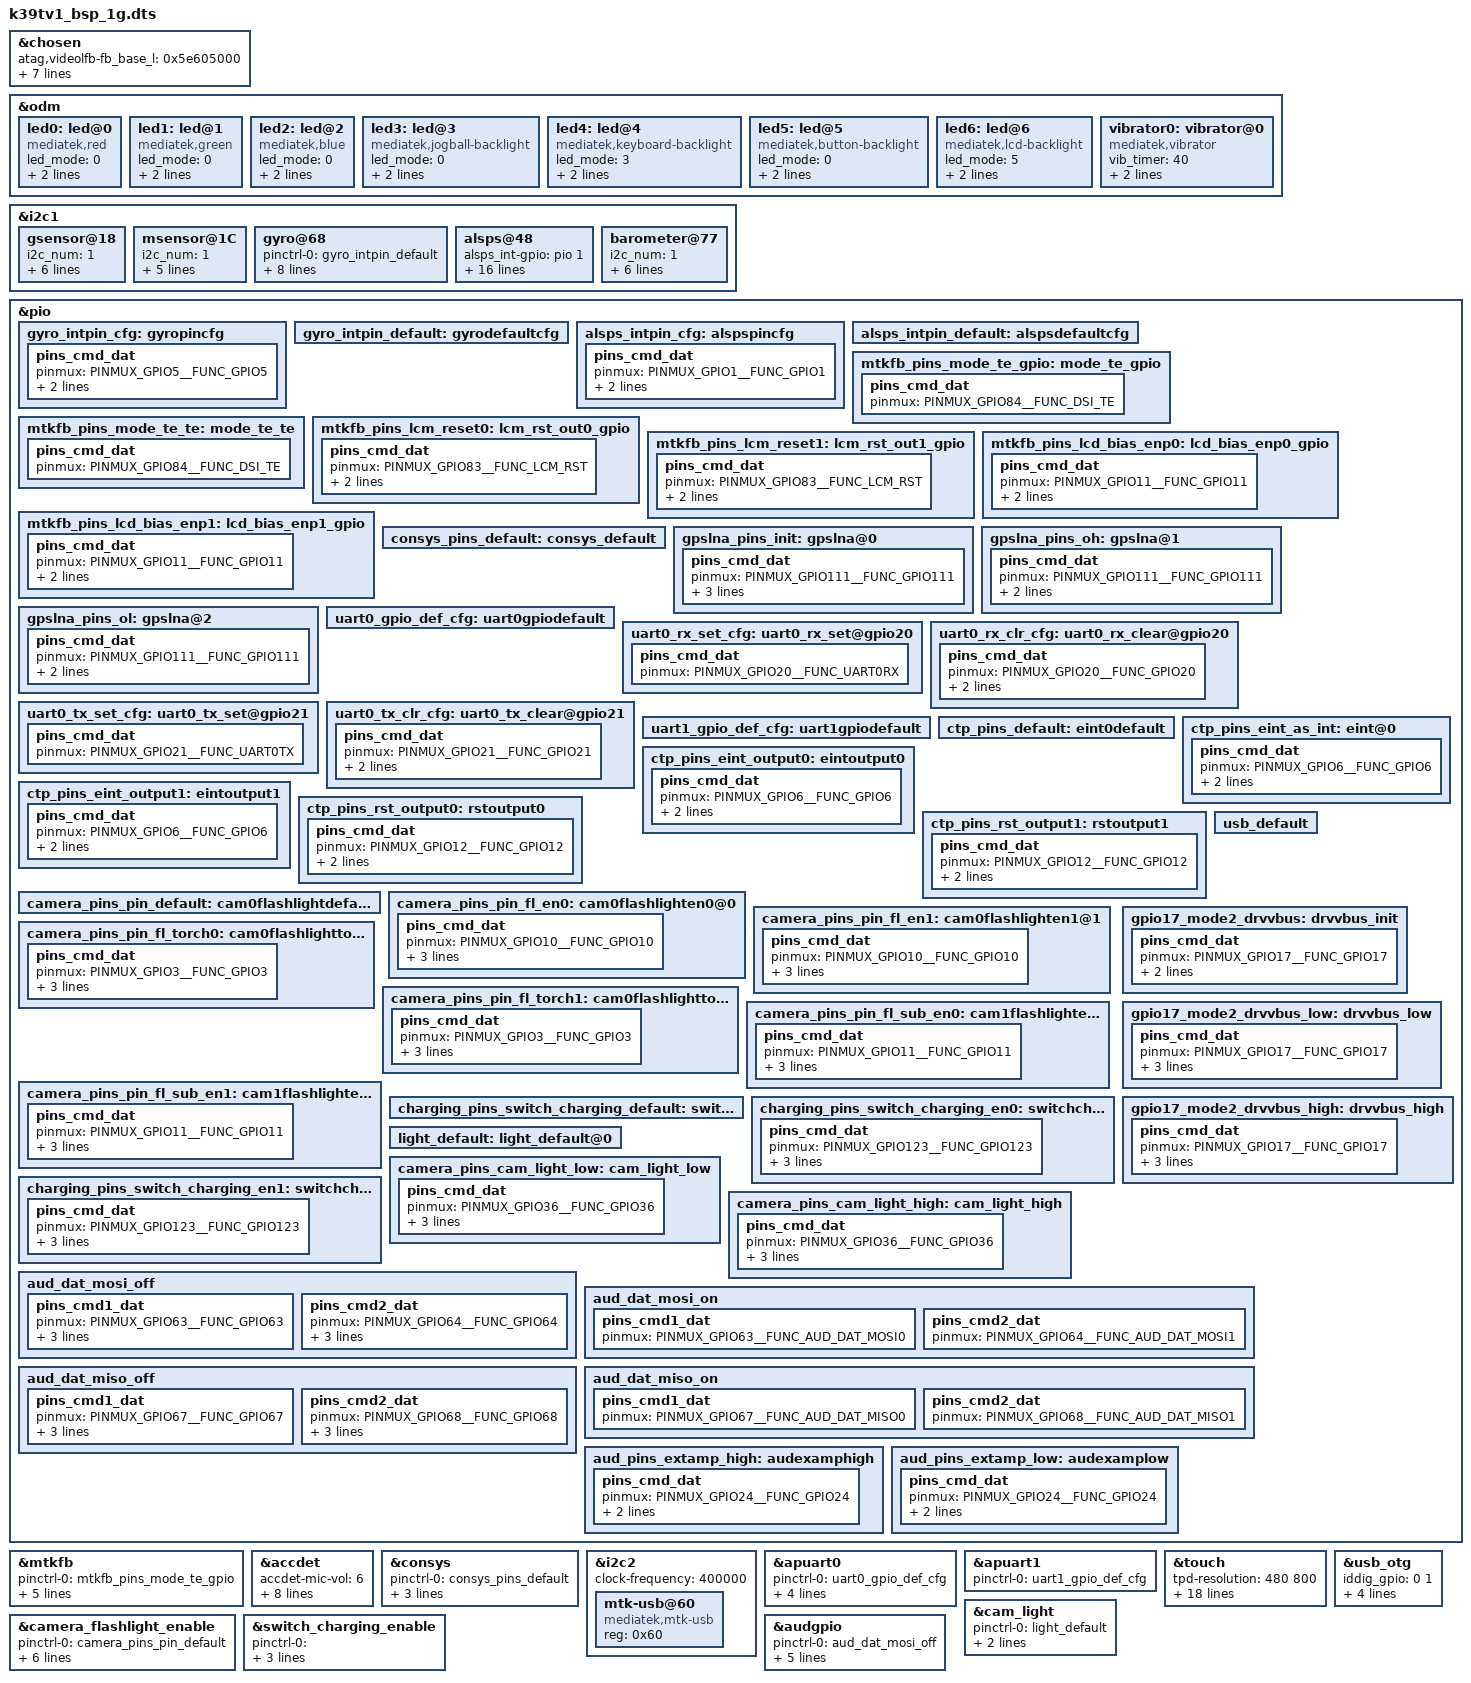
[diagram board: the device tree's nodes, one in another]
/*
 * Mediatek's MT6739 SoC device tree source
 *
 * Copyright (C) 2016 MediaTek Inc.
 *
 * This program is free software; you can redistribute it and/or modify
 * it under the terms of the GNU General Public License version 2 as
 * published by the Free Software Foundation.
 *
 * This program is distributed in the hope that it will be useful,
 * but WITHOUT ANY WARRANTY; without even the implied warranty of
 * MERCHANTABILITY or FITNESS FOR A PARTICULAR PURPOSE.
 * See http://www.gnu.org/licenses/gpl-2.0.html for more details.
 */
#include <generated/autoconf.h>
/dts-v1/;

/plugin/;
#include <dt-bindings/clock/mt6739-clk.h>
#include <dt-bindings/interrupt-controller/arm-gic.h>
#include <dt-bindings/interrupt-controller/irq.h>
#include <dt-bindings/mmc/mt6739-msdc.h>
#include <dt-bindings/pinctrl/mt6739-pinfunc.h>

/* chosen */
&chosen {
	/* fpga may has no lk, we need to specify display info here */
	/* fb buffer is reserved using this dts by memory node above */

	atag,videolfb-fb_base_l = <0x5e605000>;
	atag,videolfb-fb_base_h = <0>;
	atag,videolfb-islcmfound = <1>;
	atag,videolfb-islcm_inited = <0>;
	atag,videolfb-fps= <6000>;
	atag,videolfb-vramSize= <0x017bb000>;
	atag,videolfb-lcmname= "nt35521_hd_dsi_vdo_truly_nt50358_drv";
};

&odm {
	led0:led@0 {
		compatible = "mediatek,red";
		led_mode = <0>;
		data = <1>;
		pwm_config = <0 0 0 0 0>;
	};
	led1:led@1 {
		compatible = "mediatek,green";
		led_mode = <0>;
		data = <1>;
		pwm_config = <0 0 0 0 0>;
	};
	led2:led@2 {
		compatible = "mediatek,blue";
		led_mode = <0>;
		data = <1>;
		pwm_config = <0 0 0 0 0>;
	};
	led3:led@3 {
		compatible = "mediatek,jogball-backlight";
		led_mode = <0>;
		data = <1>;
		pwm_config = <0 0 0 0 0>;
	};
	led4:led@4 {
		compatible = "mediatek,keyboard-backlight";
		led_mode = <3>;
		data = <2>;
		pwm_config = <0 0 0 0 0>;
	};
	led5:led@5 {
		compatible = "mediatek,button-backlight";
		led_mode = <0>;
		data = <1>;
		pwm_config = <0 0 0 0 0>;
	};
	led6:led@6 {
		compatible = "mediatek,lcd-backlight";
		led_mode = <5>;
		data = <1>;
		pwm_config = <0 2 0 0 0>;
	};
	vibrator0:vibrator@0 {
		compatible = "mediatek,vibrator";
		vib_timer = <40>;
		vib_limit = <9>;
		vib_vol= <11>;
	};
};

&i2c1 {
/*  start sensor */
	 gsensor@18 {
		i2c_num = <1>;
		i2c_addr = <0x18 0 0 0>;
		direction = <6>;
		power_id = <0xffff>;
		power_vol = <0>;
		firlen = <1>;
		is_batch_supported = <0>;
	};

	msensor@1C {
		i2c_num = <1>; 
		i2c_addr = <0x1C 0 0 0>;
		direction = <6>;
		power_id = <0xffff>;
		power_vol = <0>;
		is_batch_supported = <0>;
	};

	gyro@68 {
		pinctrl-names = "pin_default", "pin_cfg";
		pinctrl-0 = <&gyro_intpin_default>;
		pinctrl-1 = <&gyro_intpin_cfg>;
		i2c_num = <1>;
		i2c_addr = <0x68 0 0 0>;
		direction = <5>;
		power_id = <0xffff>;
		power_vol = <0>;
		firlen = <0>;
		is_batch_supported = <0>;
	};

	alsps@48{
		alsps_int-gpio = <&pio 1 0>;		
		pinctrl-names = "pin_default", "pin_cfg";
		pinctrl-0 = <&alsps_intpin_default>;
		pinctrl-1 = <&alsps_intpin_cfg>;
		status = "okay";
		/* customization */
		i2c_num = <1>;
		i2c_addr = <0x48 0 0 0>;
		polling_mode_ps = <0>;
		polling_mode_als = <1>;
		power_id = <0xffff>;
		power_vol = <0>;
		als_level = <5 9 36 59 82 132 205 273 500 845 1136 1545 2364 4655 6982>;
		als_value = <10 10 80 85 90 145 225 300 550 930 1250 1700 2600 5120 7680 10240>;
		ps_threshold_high = <26>;
		ps_threshold_low = <21>;
		is_batch_supported_ps = <0>;
		is_batch_supported_als = <0>;
	};

	barometer@77 {
		i2c_num = <1>;
		i2c_addr = <0x77 0 0 0>;
		direction = <0>;
		power_id = <0xffff>;
		power_vol = <0>;
		firlen = <32>;
		is_batch_supported = <0>;
	};
/* end sensor */
};

/* sensor gpio standization */
&pio {

	gyro_intpin_cfg: gyropincfg {

	    pins_cmd_dat {
			pinmux = <PINMUX_GPIO5__FUNC_GPIO5>;
			slew-rate = <0>;
			bias-pull-down = <00>;
		};
	};

	gyro_intpin_default: gyrodefaultcfg {

	};
};

&pio {
	alsps_intpin_cfg: alspspincfg {

		pins_cmd_dat {
			pinmux = <PINMUX_GPIO1__FUNC_GPIO1>;
			slew-rate = <0>;
			bias-pull-up = <MTK_PUPD_SET_R1R0_01>;
		};
	};

	alsps_intpin_default: alspsdefaultcfg {

	};
};

/* sensor end */

/* DISPSYS GPIO standardization */
&pio {
	mtkfb_pins_mode_te_gpio: mode_te_gpio {
		pins_cmd_dat {
			pinmux = <PINMUX_GPIO84__FUNC_DSI_TE>;
		};
	};

	mtkfb_pins_mode_te_te: mode_te_te {
		pins_cmd_dat {
			pinmux = <PINMUX_GPIO84__FUNC_DSI_TE>;
		};
	};

	mtkfb_pins_lcm_reset0: lcm_rst_out0_gpio {
		pins_cmd_dat {
			pinmux = <PINMUX_GPIO83__FUNC_LCM_RST>;
			slew-rate = <1>;
			output-low;
		};
	};

	mtkfb_pins_lcm_reset1: lcm_rst_out1_gpio {
		pins_cmd_dat {
			pinmux = <PINMUX_GPIO83__FUNC_LCM_RST>;
			slew-rate = <1>;
			output-high;
		};
	};

	mtkfb_pins_lcd_bias_enp0: lcd_bias_enp0_gpio {
		pins_cmd_dat {
			pinmux = <PINMUX_GPIO11__FUNC_GPIO11>;
			slew-rate = <1>;
			output-low;
		};
	};
	mtkfb_pins_lcd_bias_enp1: lcd_bias_enp1_gpio {
		pins_cmd_dat {
			pinmux = <PINMUX_GPIO11__FUNC_GPIO11>;
			slew-rate = <1>;
			output-high;
		};
	};

};

&mtkfb {
	pinctrl-names = "mode_te_gpio", "mode_te_te", "lcm_rst_out0_gpio",
		"lcm_rst_out1_gpio", "lcd_bias_enp0_gpio", "lcd_bias_enp1_gpio";
	pinctrl-0 = <&mtkfb_pins_mode_te_gpio>;
	pinctrl-1 = <&mtkfb_pins_mode_te_te>;
	pinctrl-2 = <&mtkfb_pins_lcm_reset0>;
	pinctrl-3 = <&mtkfb_pins_lcm_reset1>;
	pinctrl-4 = <&mtkfb_pins_lcd_bias_enp0>;
	pinctrl-5 = <&mtkfb_pins_lcd_bias_enp1>;
	status = "okay";
};
/* DISPSYS GPIO standardization end */


/* accdet start */
&accdet {
	/* accdet micbias voltage: 0x07,2.7v;0x05,2.5v;0x02,1.9v */
	accdet-mic-vol = <6>;
	headset-mode-setting = <0x500 0x500 1 0x1f0 0x800 0x800 0x20 0x44>;
	accdet-plugout-debounce = <1>;
	/*1:ACC mode, 2:low cost without in bias, 6:low cost with in bias*/
	accdet-mic-mode = <2>;
/* eint_level_trigger: 8,LEVEL_LOW(default);4,LEVEL_HIGH;others,LEVEL_LOW */
	headset-eint-level-pol = <8>;
	/*0--MD_MAX--UP_MAX--DW_MAX*/
	headset-three-key-threshold = <0 80 220 400>;
	headset-three-key-threshold-CDD = <0 121 192 600>;
	/*0--MD_MAX--VOICE_MAX--UP_MAX--DW_MAX*/
	headset-four-key-threshold = <0 58 121 192 400>;
	status = "okay";
};
/* accdet end */

/* CONSYS GPIO standardization */
&pio {
	consys_pins_default: consys_default {
	};
	gpslna_pins_init: gpslna@0 {
		pins_cmd_dat {
			pinmux = <PINMUX_GPIO111__FUNC_GPIO111>;
			slew-rate = <0>;
			bias-disable;
			output-low;
		};
	};
	gpslna_pins_oh: gpslna@1 {
		pins_cmd_dat {
			pinmux = <PINMUX_GPIO111__FUNC_GPIO111>;
			slew-rate = <1>;
			output-high;
		};
	};
	gpslna_pins_ol: gpslna@2 {
		pins_cmd_dat {
			pinmux = <PINMUX_GPIO111__FUNC_GPIO111>;
			slew-rate = <1>;
			output-low;
		};
	};
};
&consys {
	pinctrl-names = "default", "gps_lna_state_init",
			"gps_lna_state_oh", "gps_lna_state_ol";
	pinctrl-0 = <&consys_pins_default>;
	pinctrl-1 = <&gpslna_pins_init>;
	pinctrl-2 = <&gpslna_pins_oh>;
	pinctrl-3 = <&gpslna_pins_ol>;
	status = "okay";
};
&i2c2 {
	#address-cells = <1>;
	#size-cells = <0>;
	clock-frequency = <400000>;

	mtk-usb@60 {
		compatible = "mediatek,mtk-usb";
		reg = <0x60>;
		status = "okay";
	};
};



/* UART GPIO */
&apuart0 {
	pinctrl-names = "uart0_gpio_default",
			"uart0_rx_set",
			"uart0_rx_clear",
			"uart0_tx_set",
			"uart0_tx_clear";
	pinctrl-0 = <&uart0_gpio_def_cfg>;
	pinctrl-1 = <&uart0_rx_set_cfg>;
	pinctrl-2 = <&uart0_rx_clr_cfg>;
	pinctrl-3 = <&uart0_tx_set_cfg>;
	pinctrl-4 = <&uart0_tx_clr_cfg>;
	status = "okay";
};

&apuart1 {
	pinctrl-names = "uart1_gpio_default";
	pinctrl-0 = <&uart1_gpio_def_cfg>;
	status = "okay";
};

&pio {
	/* UART GPIO Settings - Start */
	/* UART0: rx set, rx clear, tx clear, tx clear*/
	uart0_gpio_def_cfg:uart0gpiodefault {

	};
	uart0_rx_set_cfg:uart0_rx_set@gpio20 {
		pins_cmd_dat {
			pinmux = <PINMUX_GPIO20__FUNC_UART0RX>;
		};
	};
	uart0_rx_clr_cfg:uart0_rx_clear@gpio20 {
		pins_cmd_dat {
			pinmux = <PINMUX_GPIO20__FUNC_GPIO20>;
			slew-rate = <1>;
			output-high;
		};
	};
	uart0_tx_set_cfg:uart0_tx_set@gpio21 {
		pins_cmd_dat {
			pinmux = <PINMUX_GPIO21__FUNC_UART0TX>;
		};
	};
	uart0_tx_clr_cfg:uart0_tx_clear@gpio21 {
		pins_cmd_dat {
			pinmux = <PINMUX_GPIO21__FUNC_GPIO21>;
			slew-rate = <1>;
			output-high;
		};
	};
	/* UART1: rx set, rx clear, tx clear, tx clear*/
	uart1_gpio_def_cfg:uart1gpiodefault {

	};
};/* UART GPIO end */

/* TOUCH start */
&touch {
	tpd-resolution = <480 800>;
	use-tpd-button = <0>;
	tpd-key-num = <3>;
	tpd-key-local= <139 172 158 0>;
	tpd-key-dim-local = <90 883 100 40 230 883
				100 40 370 883 100 40 0 0 0 0>;
	tpd-max-touch-num = <5>;
	tpd-filter-enable = <1>;
	tpd-filter-pixel-density = <106>;
	tpd-filter-custom-prameters = <0 0 0 0 0 0 0 0 0 0 0 0>;
	tpd-filter-custom-speed = <0 0 0>;
	pinctrl-names = "default", "state_eint_as_int",
		"state_eint_output0", "state_eint_output1",
		"state_rst_output0", "state_rst_output1";
	pinctrl-0 = <&ctp_pins_default>;
	pinctrl-1 = <&ctp_pins_eint_as_int>;
	pinctrl-2 = <&ctp_pins_eint_output0>;
	pinctrl-3 = <&ctp_pins_eint_output1>;
	pinctrl-4 = <&ctp_pins_rst_output0>;
	pinctrl-5 = <&ctp_pins_rst_output1>;
	touch_int-gpio = <&pio 6 0>;		
	status = "okay";
};
&pio {
	ctp_pins_default: eint0default {
	};
	ctp_pins_eint_as_int: eint@0 {
		pins_cmd_dat {
			pinmux = <PINMUX_GPIO6__FUNC_GPIO6>;
			slew-rate = <0>;
			bias-disable;
		};
	};
	ctp_pins_eint_output0: eintoutput0 {
		pins_cmd_dat {
			pinmux = <PINMUX_GPIO6__FUNC_GPIO6>;
			slew-rate = <1>;
			output-low;
		};
	};
	ctp_pins_eint_output1: eintoutput1 {
		pins_cmd_dat {
			pinmux = <PINMUX_GPIO6__FUNC_GPIO6>;
			slew-rate = <1>;
			output-high;
		};
	};
	ctp_pins_rst_output0: rstoutput0 {
		pins_cmd_dat {
			pinmux = <PINMUX_GPIO12__FUNC_GPIO12>;
			slew-rate = <1>;
			output-low;
		};
	};
	ctp_pins_rst_output1: rstoutput1 {
		pins_cmd_dat {
			pinmux = <PINMUX_GPIO12__FUNC_GPIO12>;
			slew-rate = <1>;
			output-high;
		};
	};
};
/* TOUCH end */

/* CAMERA flashlight GPIO START */
&pio {

camera_pins_pin_default: cam0flashlightdefault@0 {
};
	camera_pins_pin_fl_en0: cam0flashlighten0@0 {
		    pins_cmd_dat {
				pinmux = <PINMUX_GPIO10__FUNC_GPIO10>;
				slew-rate = <1>;
				bias-disable;
				output-low;
			};
		};

	camera_pins_pin_fl_en1: cam0flashlighten1@1 {
		    pins_cmd_dat {
				pinmux = <PINMUX_GPIO10__FUNC_GPIO10>;
				slew-rate = <1>;
				bias-disable;
				output-high;
			};
		};

	camera_pins_pin_fl_torch0: cam0flashlighttorch0@0 {
		    pins_cmd_dat {
				pinmux = <PINMUX_GPIO3__FUNC_GPIO3>;
				slew-rate = <1>;
				bias-disable;
				output-low;
			};
		};

	camera_pins_pin_fl_torch1: cam0flashlighttorch1@1 {
		    pins_cmd_dat {
				pinmux = <PINMUX_GPIO3__FUNC_GPIO3>;
				slew-rate = <1>;
				bias-disable;
				output-high;
			};
		};

       camera_pins_pin_fl_sub_en0: cam1flashlighten0@0 {
		    pins_cmd_dat {
				pinmux = <PINMUX_GPIO11__FUNC_GPIO11>;
				slew-rate = <1>;
				bias-disable;
				output-low;
			};
		};

	camera_pins_pin_fl_sub_en1: cam1flashlighten1@1 {
		    pins_cmd_dat {
				pinmux = <PINMUX_GPIO11__FUNC_GPIO11>;
				slew-rate = <1>;
				bias-disable;
				output-high;
			};
		};

};

&camera_flashlight_enable {
	pinctrl-names = "pin_default", "pin_fl_en0", "pin_fl_en1","pin_fl_torch0", "pin_fl_torch1", "pin_fl_sub_en0", "pin_fl_sub_en1";
	pinctrl-0 = <&camera_pins_pin_default>;
 	pinctrl-1 = <&camera_pins_pin_fl_en0>;  
	pinctrl-2 = <&camera_pins_pin_fl_en1>;
	pinctrl-3 = <&camera_pins_pin_fl_torch0>;  
	pinctrl-4 = <&camera_pins_pin_fl_torch1>;
	pinctrl-5 = <&camera_pins_pin_fl_sub_en0>;  
	pinctrl-6 = <&camera_pins_pin_fl_sub_en1>;
	status = "okay";
};
/* CAMERA flashlight GPIO END */
/* charging  GPIO START */
&pio {

charging_pins_switch_charging_default: switchchargdefault@0 {
};

charging_pins_switch_charging_en0: switchchargen0@0 {
	    pins_cmd_dat {
			pinmux = <PINMUX_GPIO123__FUNC_GPIO123>;
			slew-rate = <1>;
			bias-disable;
			output-low;
		};
	};
charging_pins_switch_charging_en1: switchchargen1@1 {
	    pins_cmd_dat {
			pinmux = <PINMUX_GPIO123__FUNC_GPIO123>;
			slew-rate = <1>;
			bias-disable;
			output-high;
		};
	};
};

&switch_charging_enable {
	pinctrl-names = "switch_charging_default", "switch_charging_en0", "switch_charging_en1";
	pinctrl-0 = <&charging_pins_switch_charging_default>;
 	pinctrl-1 = <&charging_pins_switch_charging_en0>;  
	pinctrl-2 = <&charging_pins_switch_charging_en1>;
	status = "okay";
};
/* charging GPIO END */


/* USB GPIO Kernal Standardization start */
&pio {
        usb_default: usb_default {
        };

        gpio17_mode2_drvvbus: drvvbus_init {
                pins_cmd_dat {
                        pinmux = <PINMUX_GPIO17__FUNC_GPIO17>;
                        slew-rate = <1>;
                        bias-pull-down = <00>;
                };
        };

        gpio17_mode2_drvvbus_low: drvvbus_low {
                pins_cmd_dat {
                        pinmux = <PINMUX_GPIO17__FUNC_GPIO17>;
                        slew-rate = <1>;
                        output-low;
                        bias-pull-down = <00>;
                };
        };

        gpio17_mode2_drvvbus_high: drvvbus_high {
                pins_cmd_dat {
                        pinmux = <PINMUX_GPIO17__FUNC_GPIO17>;
                        slew-rate = <1>;
                        output-high;
                        bias-pull-down = <00>;
                };
        };
};

&usb_otg {
        iddig_gpio = <0 1>;
        pinctrl-names = "usb_default", "drvvbus_init", "drvvbus_low", "drvvbus_high";
        pinctrl-0 = <&usb_default>;
        pinctrl-1 = <&gpio17_mode2_drvvbus>;
        pinctrl-2 = <&gpio17_mode2_drvvbus_low>;
        pinctrl-3 = <&gpio17_mode2_drvvbus_high>;
        status = "okay";
};
/* USB GPIO Kernal Standardization end */

/* camera light Kernal Standardization start */
&pio {
        light_default: light_default@0 {
        };

        camera_pins_cam_light_low: cam_light_low {
                pins_cmd_dat {
                        pinmux = <PINMUX_GPIO36__FUNC_GPIO36>;
                        slew-rate = <1>;
                        output-low;
                        bias-pull-down = <00>;
                };
        };

        camera_pins_cam_light_high: cam_light_high {
                pins_cmd_dat {
                        pinmux = <PINMUX_GPIO36__FUNC_GPIO36>;
                        slew-rate = <1>;
                        output-high;
                        bias-pull-down = <00>;
                };
        };
       
};

&cam_light {
        pinctrl-names = "light_default","cam_light_low", "cam_light_high";
        pinctrl-0 = <&light_default>;
        pinctrl-1 = <&camera_pins_cam_light_low>;
        pinctrl-2 = <&camera_pins_cam_light_high>;
        status = "okay";
};
/* camera light Kernal Standardization end */

/* AUDIO GPIO standardization */
&audgpio {
	pinctrl-names = "aud_dat_mosi_off",
			"aud_dat_mosi_on",
			"aud_dat_miso_off",
			"aud_dat_miso_on",
			"extamp-pullhigh",
			"extamp-pulllow";
	pinctrl-0 = <&aud_dat_mosi_off>;
	pinctrl-1 = <&aud_dat_mosi_on>;
	pinctrl-2 = <&aud_dat_miso_off>;
	pinctrl-3 = <&aud_dat_miso_on>;
	pinctrl-4 = <&aud_pins_extamp_high>;
	pinctrl-5 = <&aud_pins_extamp_low>;
	status = "okay";
};

&pio {
	aud_dat_mosi_off: aud_dat_mosi_off {
		pins_cmd1_dat {
			pinmux = <PINMUX_GPIO63__FUNC_GPIO63>;
			input-enable;
			slew-rate = <0>;
			bias-disable;
		};
		pins_cmd2_dat {
			pinmux = <PINMUX_GPIO64__FUNC_GPIO64>;
			input-enable;
			slew-rate = <0>;
			bias-disable;
		};
	};

	aud_dat_mosi_on: aud_dat_mosi_on {
		pins_cmd1_dat {
			pinmux = <PINMUX_GPIO63__FUNC_AUD_DAT_MOSI0>;
		};
		pins_cmd2_dat {
			pinmux = <PINMUX_GPIO64__FUNC_AUD_DAT_MOSI1>;
		};
	};

	aud_dat_miso_off: aud_dat_miso_off {
		pins_cmd1_dat {
			pinmux = <PINMUX_GPIO67__FUNC_GPIO67>;
			input-enable;
			slew-rate = <0>;
			bias-disable;
		};
		pins_cmd2_dat {
			pinmux = <PINMUX_GPIO68__FUNC_GPIO68>;
			input-enable;
			slew-rate = <0>;
			bias-disable;
		};
	};

	aud_dat_miso_on: aud_dat_miso_on {
		pins_cmd1_dat {
			pinmux = <PINMUX_GPIO67__FUNC_AUD_DAT_MISO0>;
		};
		pins_cmd2_dat {
			pinmux = <PINMUX_GPIO68__FUNC_AUD_DAT_MISO1>;
		};
	};
	aud_pins_extamp_high: audexamphigh {
		pins_cmd_dat {
			pinmux = <PINMUX_GPIO24__FUNC_GPIO24>;
			slew-rate = <1>;
			output-high;
		};
	};

	aud_pins_extamp_low: audexamplow {
		pins_cmd_dat {
			pinmux = <PINMUX_GPIO24__FUNC_GPIO24>;
			slew-rate = <1>;
			output-low;
		};
	};

};
/* AUDIO end */

#include <k39tv1_bsp_1g/cust.dtsi>
#include "cust_mt6739_camera.dtsi"
/*End of this file, DO NOT ADD ANYTHING HERE*/
